# BS2X register map
File version: 0.1
CPU: other r0p0, little endian, MPU, FPU, 3 interrupt priority bits
Registers are 32-bit, read-write, reset 0x0 unless marked. A register's access mark holds for its fields unless they carry their own. Offsets are from the block's base; [hi:lo] are bit positions.

## RTC — RTC v150 instance 0 register block
Base 0x57024100
0x00 LOAD_COUNT0
0x04 LOAD_COUNT1
0x08 CURRENT_VALUE0 ro
0x0C CURRENT_VALUE1 ro
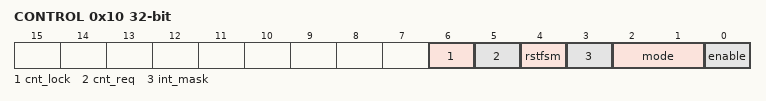
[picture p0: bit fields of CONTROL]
0x10 CONTROL
  [6] cnt_lock, [5] cnt_req, [4] rstfsm, [3] int_mask, [2:1] mode, [0] enable
0x14 EOI_REN
  [0] eoi
0x18 RAW_INTR
  [0] int_status
0x1C INTR
  [0] int_status

## TRNG — True random number generator (v1)
Base 0x52009000
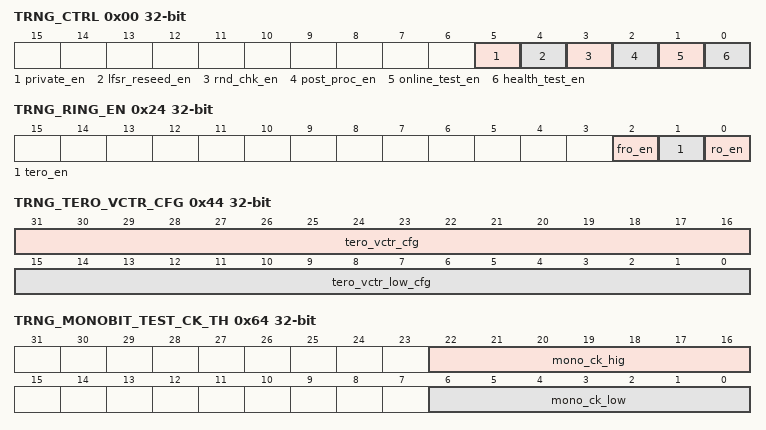
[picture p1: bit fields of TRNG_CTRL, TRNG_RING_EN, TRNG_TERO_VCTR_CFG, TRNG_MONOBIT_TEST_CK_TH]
0x00 TRNG_CTRL
  [5] private_en, [4] lfsr_reseed_en, [3] rnd_chk_en, [2] post_proc_en, [1] online_test_en, [0] health_test_en
0x04 TRNG_SRC_SEL
  [1:0] trng_sel
0x08 TRNG_FRO_SEL
  [4:0] fro_sel
0x10 TRNG_ALL_REG_LOCK
  [0] trng_all_reg_lock
0x20 TRNG_LOW_POWER_ENABLE
  [0] trng_low_power_enable
0x24 TRNG_RING_EN
  [2] fro_en, [1] tero_en, [0] ro_en
0x30 TRNG_RO_TIMER_CNT
  [15:0] ro_timer_cnt
0x40 TRNG_TERO_BIT_SEL
  [1:0] tero_bit_sel
0x44 TRNG_TERO_VCTR_CFG
  [31:16] tero_vctr_cfg, [15:0] tero_vctr_low_cfg
0x60 TRNG_ONLINE_TEST_FAIL_CK_TH
  [3:0] online_test_fail_ck_cnt
0x64 TRNG_MONOBIT_TEST_CK_TH
  [22:16] mono_ck_hig, [6:0] mono_ck_low
0x68 TRNG_LONG_RUN_TEST_CK_TH
  [7:0] long_run_hig
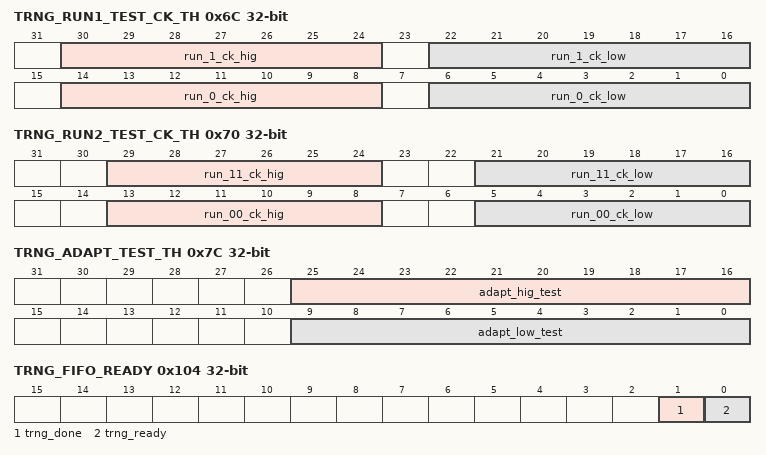
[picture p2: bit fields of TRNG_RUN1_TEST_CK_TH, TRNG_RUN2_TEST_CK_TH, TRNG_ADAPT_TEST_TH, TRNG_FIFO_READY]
0x6C TRNG_RUN1_TEST_CK_TH
  [30:24] run_1_ck_hig, [22:16] run_1_ck_low, [14:8] run_0_ck_hig, [6:0] run_0_ck_low
0x70 TRNG_RUN2_TEST_CK_TH
  [29:24] run_11_ck_hig, [21:16] run_11_ck_low, [13:8] run_00_ck_hig, [5:0] run_00_ck_low
0x74 TRNG_POKER_TEST_CK_TH
  [10:0] poker_ck_hig
0x78 TRNG_RPT_TEST_TH
  [7:0] rpt_cnt_test
0x7C TRNG_ADAPT_TEST_TH
  [25:16] adapt_hig_test, [9:0] adapt_low_test
0x80 TRNG_TOTAL_FAILURE_TEST_CK_TH
  [10:0] total_failure_ck_hig
0x84 TRNG_RND_TEST_FAIL_CK_TH
  [2:0] rnd_fail_ck_cnt
0x100 TRNG_FIFO_DATA ro
  [31:0] trng_data
0x104 TRNG_FIFO_READY
  [1] trng_done, [0] trng_ready
0x108 TRNG_DATA_ST
  [4:0] rng_fifo_real_cnt
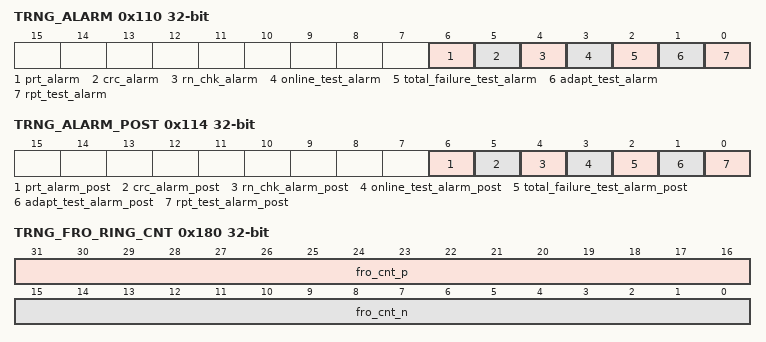
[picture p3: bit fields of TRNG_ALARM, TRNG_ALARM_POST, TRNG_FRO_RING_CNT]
0x110 TRNG_ALARM
  [6] prt_alarm, [5] crc_alarm, [4] rn_chk_alarm, [3] online_test_alarm, [2] total_failure_test_alarm, [1] adapt_test_alarm, [0] rpt_test_alarm
0x114 TRNG_ALARM_POST
  [6] prt_alarm_post, [5] crc_alarm_post, [4] rn_chk_alarm_post, [3] online_test_alarm_post, [2] total_failure_test_alarm_post, [1] adapt_test_alarm_post, [0] rpt_test_alarm_post
0x118 TRNG_ALARM_MASK
  [4:0] trng_alarm_mask
0x11C TRNG_ALARM_CLR
  [0] trng_alarm_clr
0x160 TRNG_TERO_CNT_SEL
  [3:0] tero_cnt_sel
0x164 TRNG_TERO_RING_CNT
  [15:0] tero_ring_cnt
0x170 TRNG_FRO_FORCE_RST
  [0] fro_force_rst_n
0x174 TRNG_FRO_SAMPLE_CLK_SEL
  [0] fro_sample_clk_sel
0x178 TRNG_FRO_DIV_CNT
  [7:0] fro_div_cnt
0x17C TRNG_FRO_CNT_SEL
  [4:0] fro_cnt_sel
0x180 TRNG_FRO_RING_CNT
  [31:16] fro_cnt_p, [15:0] fro_cnt_n
0x184 TRNG_FRO_DIV_CLK_CNT
0x188 TRNG_FRO_CNT_CLK_CNT
0x1E0 TRNG_REAL_CLOCK_EN
  [5:0] low_power_en
0x200 TRNG_VER_NUM

## KEYSCAN — Key-scan matrix controller (v150)
Base 0x5208D000
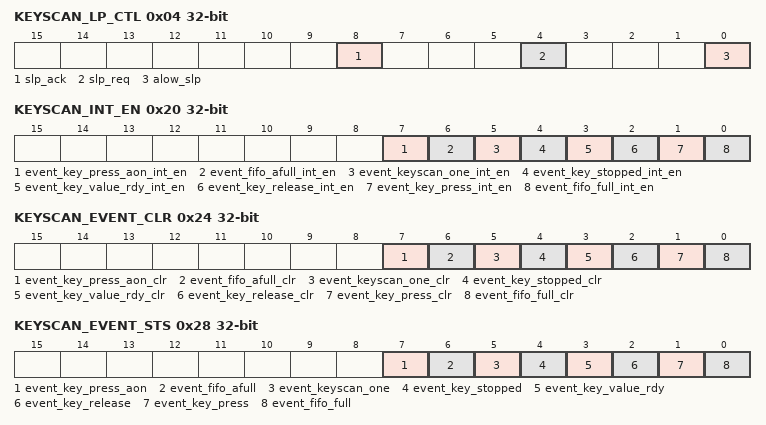
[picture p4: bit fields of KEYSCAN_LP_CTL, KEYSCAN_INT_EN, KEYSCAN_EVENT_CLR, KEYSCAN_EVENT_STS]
0x04 KEYSCAN_LP_CTL
  [8] slp_ack, [4] slp_req, [0] alow_slp
0x08 KEYSCAN_ENABLE
  [0] ena
0x0C KEYSCAN_CLK_ENA
  [0] fifo_rd_clken
0x10 KEYSCAN_START
  [0] task_start
0x20 KEYSCAN_INT_EN
  [7] event_key_press_aon_int_en, [6] event_fifo_afull_int_en, [5] event_keyscan_one_int_en, [4] event_key_stopped_int_en, [3] event_key_value_rdy_int_en, [2] event_key_release_int_en, [1] event_key_press_int_en, [0] event_fifo_full_int_en
0x24 KEYSCAN_EVENT_CLR
  [7] event_key_press_aon_clr, [6] event_fifo_afull_clr, [5] event_keyscan_one_clr, [4] event_key_stopped_clr, [3] event_key_value_rdy_clr, [2] event_key_release_clr, [1] event_key_press_clr, [0] event_fifo_full_clr
0x28 KEYSCAN_EVENT_STS
  [7] event_key_press_aon, [6] event_fifo_afull, [5] event_keyscan_one, [4] event_key_stopped, [3] event_key_value_rdy, [2] event_key_release, [1] event_key_press, [0] event_fifo_full
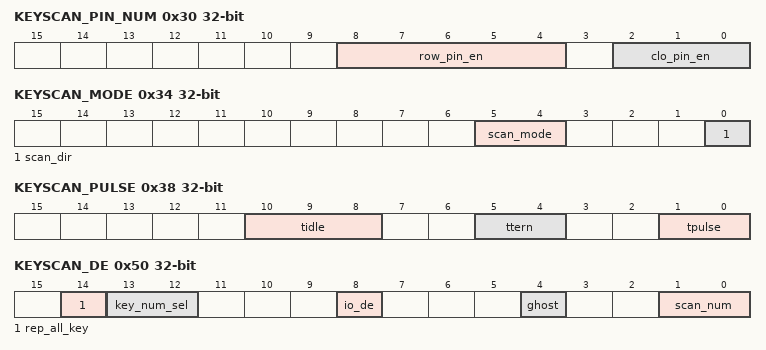
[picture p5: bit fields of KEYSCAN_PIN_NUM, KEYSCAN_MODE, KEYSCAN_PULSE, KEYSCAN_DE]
0x30 KEYSCAN_PIN_NUM
  [8:4] row_pin_en, [2:0] clo_pin_en
0x34 KEYSCAN_MODE
  [5:4] scan_mode, [0] scan_dir
0x38 KEYSCAN_PULSE
  [10:8] tidle, [5:4] ttern, [1:0] tpulse
0x50 KEYSCAN_DE
  [14] rep_all_key, [13:12] key_num_sel, [8] io_de, [4] ghost, [1:0] scan_num
0x94 KEY_VALUE_FIFO
  [8:0] key_value

## PDM — PDM microphone interface (v150)
Base 0x5208E000
0x00 VERSION
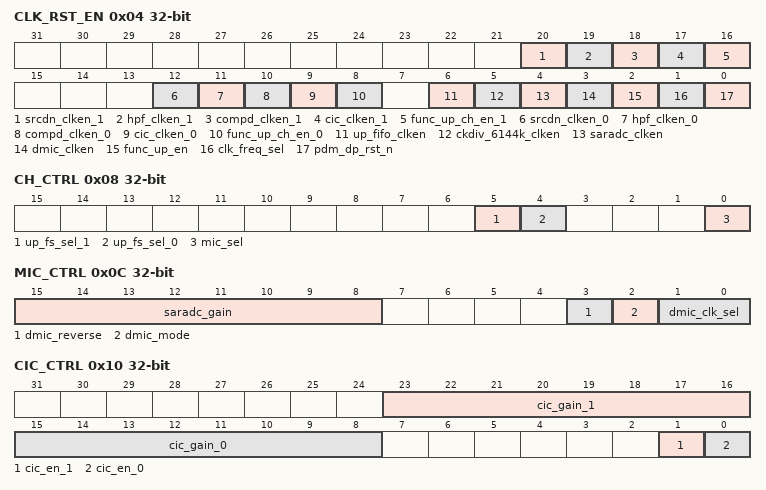
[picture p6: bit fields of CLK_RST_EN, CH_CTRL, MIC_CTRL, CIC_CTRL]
0x04 CLK_RST_EN
  [20] srcdn_clken_1, [19] hpf_clken_1, [18] compd_clken_1, [17] cic_clken_1, [16] func_up_ch_en_1, [12] srcdn_clken_0, [11] hpf_clken_0, [10] compd_clken_0, [9] cic_clken_0, [8] func_up_ch_en_0, [6] up_fifo_clken, [5] ckdiv_6144k_clken, [4] saradc_clken, [3] dmic_clken, [2] func_up_en, [1] clk_freq_sel, [0] pdm_dp_rst_n
0x08 CH_CTRL
  [5] up_fs_sel_1, [4] up_fs_sel_0, [0] mic_sel
0x0C MIC_CTRL
  [15:8] saradc_gain, [3] dmic_reverse, [2] dmic_mode, [1:0] dmic_clk_sel
0x10 CIC_CTRL
  [23:16] cic_gain_1, [15:8] cic_gain_0, [1] cic_en_1, [0] cic_en_0
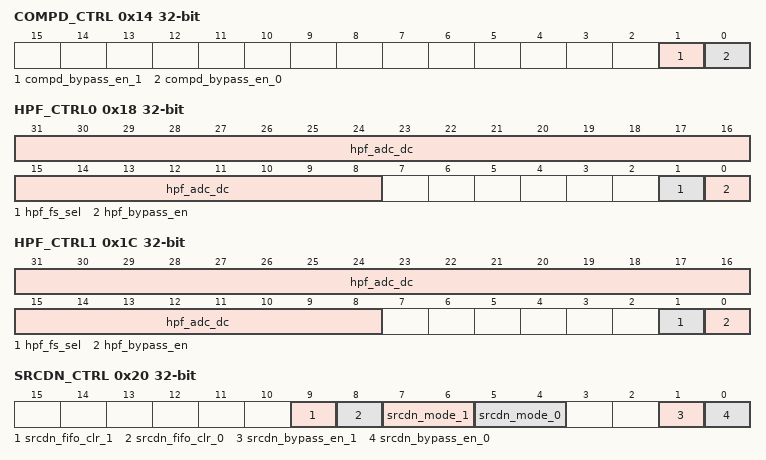
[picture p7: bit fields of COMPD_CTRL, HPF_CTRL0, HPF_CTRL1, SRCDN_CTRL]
0x14 COMPD_CTRL
  [1] compd_bypass_en_1, [0] compd_bypass_en_0
0x18 HPF_CTRL0 — hpf_ctrl channel 0
  [31:8] hpf_adc_dc, [1] hpf_fs_sel, [0] hpf_bypass_en
0x1C HPF_CTRL1 — hpf_ctrl channel 1
  [31:8] hpf_adc_dc, [1] hpf_fs_sel, [0] hpf_bypass_en
0x20 SRCDN_CTRL
  [9] srcdn_fifo_clr_1, [8] srcdn_fifo_clr_0, [7:6] srcdn_mode_1, [5:4] srcdn_mode_0, [1] srcdn_bypass_en_1, [0] srcdn_bypass_en_0
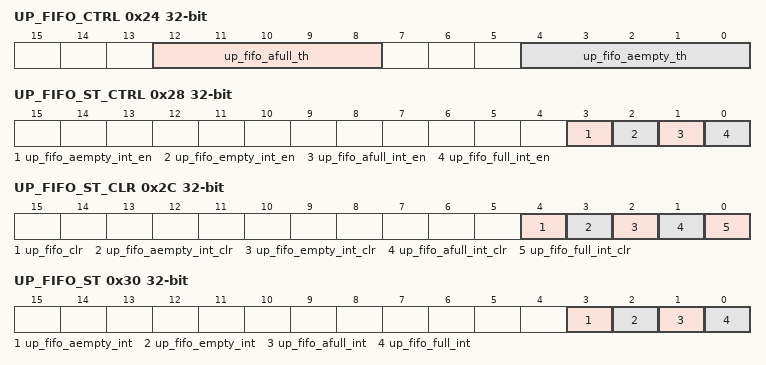
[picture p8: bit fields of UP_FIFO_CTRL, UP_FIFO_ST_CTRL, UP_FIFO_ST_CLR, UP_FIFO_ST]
0x24 UP_FIFO_CTRL
  [12:8] up_fifo_afull_th, [4:0] up_fifo_aempty_th
0x28 UP_FIFO_ST_CTRL
  [3] up_fifo_aempty_int_en, [2] up_fifo_empty_int_en, [1] up_fifo_afull_int_en, [0] up_fifo_full_int_en
0x2C UP_FIFO_ST_CLR
  [4] up_fifo_clr, [3] up_fifo_aempty_int_clr, [2] up_fifo_empty_int_clr, [1] up_fifo_afull_int_clr, [0] up_fifo_full_int_clr
0x30 UP_FIFO_ST ro
  [3] up_fifo_aempty_int, [2] up_fifo_empty_int, [1] up_fifo_afull_int, [0] up_fifo_full_int
0x80 UP_FIFO_DATA ro — UP FIFO 32-bit PCM sample data window
  [31:0] pcm_word

## QDEC — Quadrature decoder (v150)
Base 0x52000200
0x04 QDEC_TASK_START
  [0] start
0x08 QDEC_TASK_STOP
  [0] stop
0x0C QDEC_TASK_READCLR_ACC
  [0] readclr_acc
0x10 QDEC_TASK_RD_CLR_ACC
  [0] rd_clr_acc
0x14 QDEC_TASK_RD_CLR_DBL
  [0] rd_clr_dbl
0x18 QDEC_ENABLE
  [0] en
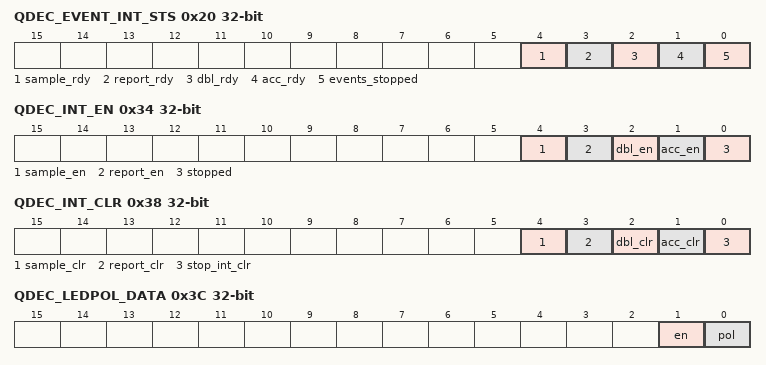
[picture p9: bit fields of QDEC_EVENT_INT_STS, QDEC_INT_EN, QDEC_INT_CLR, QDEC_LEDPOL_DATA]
0x20 QDEC_EVENT_INT_STS
  [4] sample_rdy, [3] report_rdy, [2] dbl_rdy, [1] acc_rdy, [0] events_stopped
0x34 QDEC_INT_EN
  [4] sample_en, [3] report_en, [2] dbl_en, [1] acc_en, [0] stopped
0x38 QDEC_INT_CLR
  [4] sample_clr, [3] report_clr, [2] dbl_clr, [1] acc_clr, [0] stop_int_clr
0x3C QDEC_LEDPOL_DATA
  [1] en, [0] pol
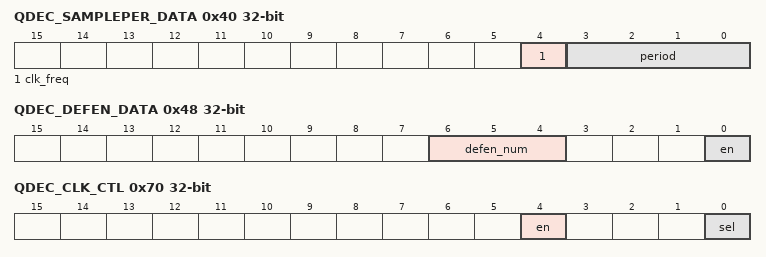
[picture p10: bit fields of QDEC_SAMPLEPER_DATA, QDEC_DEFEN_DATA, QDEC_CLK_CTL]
0x40 QDEC_SAMPLEPER_DATA
  [4] clk_freq, [3:0] period
0x44 QDEC_REPORTER_DATA
  [2:0] samlple_repo_val
0x48 QDEC_DEFEN_DATA
  [6:4] defen_num, [0] en
0x4C QDEC_LEDPRE_DATA
  [9:0] led_pre
0x50 QDEC_SAMPLE_DATA
  [2:0] sample_val
0x54 QDEC_ACC_DATA
  [15:0] acc_rd_val
0x58 QDEC_ACCDBL_DATA
  [3:0] dbl_rd_val
0x5C QDEC_ACC_READ
  [15:0] acc_rd_val_shadow
0x60 QDEC_ACCDBL_READ
  [3:0] dbl_rd_val_shadow
0x64 QDEC_ACC_EVENT
  [8:0] acc_event_cnt
0x68 QDEC_FPGA_IO_SEL
  [0] fpga_io_src
0x70 QDEC_CLK_CTL
  [4] en, [0] sel
0x74 QDEC_SOFT_RST
  [0] soft_rst

## ADC_PMU_AFE — ADC PMU AFE power/isolation/reset block
Base 0x57008700
0x00 AFE_ADC_RST_N
  [0] afe_adc_rst_n
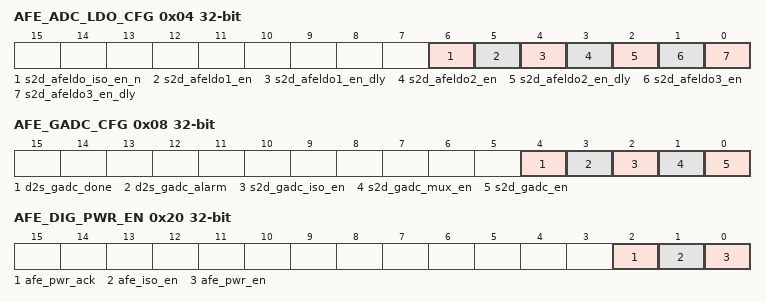
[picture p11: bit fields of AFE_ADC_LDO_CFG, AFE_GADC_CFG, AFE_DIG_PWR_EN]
0x04 AFE_ADC_LDO_CFG
  [6] s2d_afeldo_iso_en_n, [5] s2d_afeldo1_en, [4] s2d_afeldo1_en_dly, [3] s2d_afeldo2_en, [2] s2d_afeldo2_en_dly, [1] s2d_afeldo3_en, [0] s2d_afeldo3_en_dly
0x08 AFE_GADC_CFG
  [4] d2s_gadc_done, [3] d2s_gadc_alarm, [2] s2d_gadc_iso_en, [1] s2d_gadc_mux_en, [0] s2d_gadc_en
0x0C AFE_GADC_DATA_L
0x10 AFE_GADC_DATA_H
0x14 AFE_HADC_CFG
0x18 AFE_HADC_DATA_L
0x1C AFE_HADC_DATA_H
0x20 AFE_DIG_PWR_EN
  [2] afe_pwr_ack, [1] afe_iso_en, [0] afe_pwr_en
0x24 AFE_SOFT_RST
  [0] afe_soft_rst
0x28 AFE_CLK_EN
  [0] afe_clk_en
0x2C AFE_CMP_ALARM_EN
0x30 AFE_ISO_CFG

## AON_AFE — AON AFE isolation control used by the BS2X ADC porting layer
Base 0x5702C000
0x230 AFE_ISO — AFE isolation control at 0x5702C230
  [10] afe_iso_en
